# EFR32FG23A020F512GM40 register map
Vendor: Silicon Labs; Series: EFR32; File version: B
Registers are 32-bit, read-write, reset 0x0 unless marked. A register's access mark holds for its fields unless they carry their own. Offsets are from the block's base; [hi:lo] are bit positions.

## LFRCO_S — LFRCO_S Registers
Base 0x40024000
Same registers: LFRCO_NS 0x50024000
0x00 IPVERSION ro — Contains the LFRCO ip version.
  [31:0] IPVERSION — IP version ID
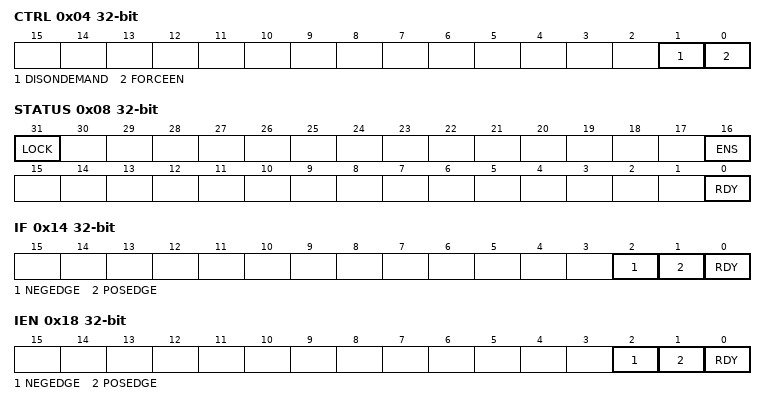
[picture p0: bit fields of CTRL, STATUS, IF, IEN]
0x04 CTRL — Control register
  [1] DISONDEMAND — Disable On-Demand
  [0] FORCEEN — Force Enable
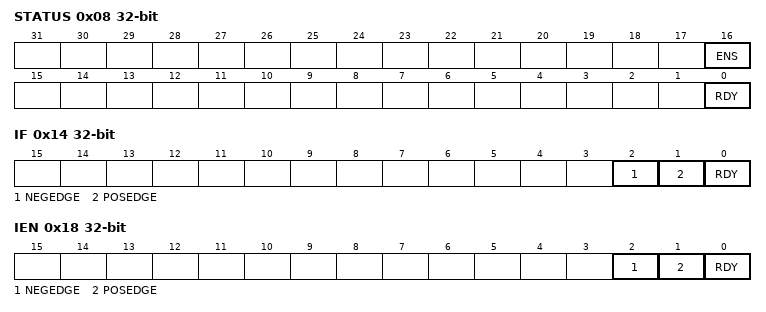
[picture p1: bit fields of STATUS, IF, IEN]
0x08 STATUS ro
  [31] LOCK — Lock Status
    0=UNLOCKED (Access to configuration registers not locked); 1=LOCKED (Access to configuration registers locked)
  [16] ENS — Enabled Status
  [0] RDY — Ready Status
0x0C CAL reset 0xA5 — Calibration register
  [7:0] FREQTRIM — Frequency Trim
0x14 IF — Interrupt flag register
  [2] NEGEDGE — Falling Edge Interrupt Flag
  [1] POSEDGE — Rising Edge Interrupt Flag
  [0] RDY — Ready Interrupt Flag
0x18 IEN — Interrupt enable register.
  [2] NEGEDGE — Falling Edge Interrupt Enable
  [1] POSEDGE — Rising Edge Interrupt Enable
  [0] RDY — Ready Interrupt Enable
0x1C SYNCBUSY ro — Synchronization busy register
  [0] CAL — CAL Busy
0x20 LOCK wo reset 0x2603 — Configuration lock register. Locks/unlocks access to cofiguration registers.
  [15:0] LOCKKEY
    0=LOCK (Lock Configuration Registers); 0x2603=UNLOCK (Unlock Configuaration Registers)

## ULFRCO_S — ULFRCO_S Registers
Base 0x40028000
Same registers: ULFRCO_NS 0x50028000
0x00 IPVERSION ro reset 0x1
  [31:0] IPVERSION — ULFRCO IP version
0x08 STATUS ro
  [16] ENS — Enable Status
  [0] RDY — Ready Status
0x14 IF
  [2] NEGEDGE — Negative Edge Interrupt Flag
  [1] POSEDGE — Positive Edge Interrupt Flag
  [0] RDY — Ready Interrupt Flag
0x18 IEN
  [2] NEGEDGE — Enable Negative Edge Interrupt
  [1] POSEDGE — Enable Positive Edge Interrupt
  [0] RDY — Enable Ready Interrupt

## MSC_S — MSC_S Registers
Base 0x40030000
Same registers: MSC_NS 0x50030000
0x00 IPVERSION ro reset 0x2
  [31:0] IPVERSION — IP Version ID
0x04 READCTRL reset 0x200000
  [21:20] MODE — Read Mode
    0=WS0 (Zero wait-states inserted in fetch or read transfers); 1=WS1 (One wait-state inserted for each fetch or read transfer. See Flash Wait-States table for details); 2=WS2 (Two wait-states inserted for eatch fetch or read transfer. See Flash Wait-States table for details); 3=WS3 (Three wait-states inserted for eatch fetch or read transfer. See Flash Wait-States table for details)
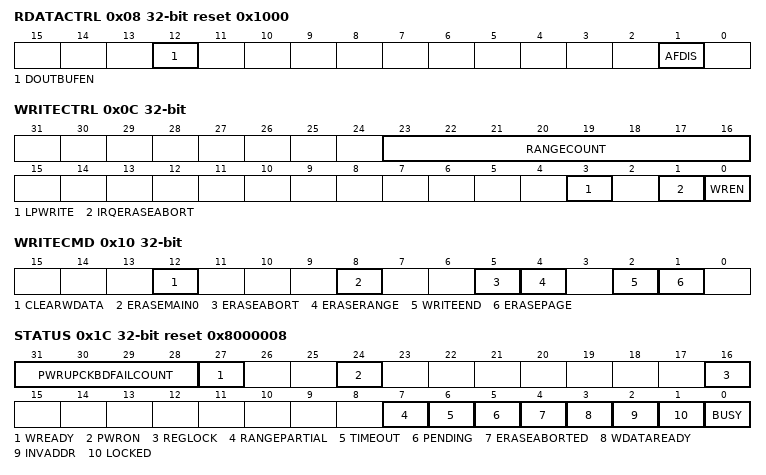
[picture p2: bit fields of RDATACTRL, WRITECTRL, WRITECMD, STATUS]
0x08 RDATACTRL reset 0x1000
  [12] DOUTBUFEN — Flash dout pipeline buffer enable
  [1] AFDIS — Automatic Invalidate Disable
0x0C WRITECTRL
  [23:16] RANGECOUNT — ErageRange Count
  [3] LPWRITE — Low-Power Erase
  [1] IRQERASEABORT — Abort Page Erase on Interrupt
  [0] WREN — Enable Write/Erase Controller
0x10 WRITECMD wo
  [12] CLEARWDATA — Clear WDATA state
  [8] ERASEMAIN0 — Mass erase region 0
  [5] ERASEABORT — Abort erase sequence
  [4] ERASERANGE — Erase range of pages
  [2] WRITEEND — End Write Mode
  [1] ERASEPAGE
0x14 ADDRB
  [31:0] ADDRB — Page Erase or Write Address Buffer
0x18 WDATA
  [31:0] DATAW — Write Data
0x1C STATUS ro reset 0x8000008
  [31:28] PWRUPCKBDFAILCOUNT — Flash power up checkerboard pattern chec
  [27] WREADY — Flash Write Ready
  [24] PWRON — Flash power on status
  [16] REGLOCK — Register Lock Status
    0=UNLOCKED; 1=LOCKED
  [7] RANGEPARTIAL — EraseRange with skipped locked pages
  [6] TIMEOUT — Write command timeout flag
  [5] PENDING — Write command is in queue
  [4] ERASEABORTED — The Current Flash Erase Operation Aborte
  [3] WDATAREADY — WDATA Write Ready
  [2] INVADDR — Invalid Write Address or Erase Page
  [1] LOCKED — Access Locked
  [0] BUSY — Erase/Write Busy
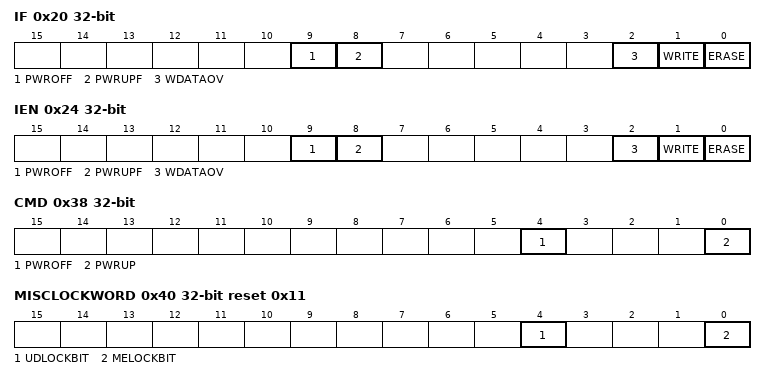
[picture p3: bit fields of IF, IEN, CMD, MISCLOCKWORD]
0x20 IF
  [9] PWROFF — Flash Power Off Sequence Complete Flag
  [8] PWRUPF — Flash Power Up Sequence Complete Flag
  [2] WDATAOV — Host write buffer overflow
  [1] WRITE — Host Write Done Interrupt Read Flag
  [0] ERASE — Host Erase Done Interrupt Read Flag
0x24 IEN
  [9] PWROFF — Flash Power Off Seq done irq enable
  [8] PWRUPF — Flash Power Up Seq done irq enable
  [2] WDATAOV — write data buffer overflow irq enable
  [1] WRITE — Write Done Interrupt enable
  [0] ERASE — Erase Done Interrupt enable
0x34 USERDATASIZE ro reset 0x4
  [5:0] USERDATASIZE
0x38 CMD wo
  [4] PWROFF — Flash power off/sleep command
  [0] PWRUP — Flash Power Up Command
0x3C LOCK wo
  [15:0] LOCKKEY — Configuration Lock
    0=LOCK; 0x1B71=UNLOCK
0x40 MISCLOCKWORD reset 0x11
  [4] UDLOCKBIT — User Data Lock
  [0] MELOCKBIT — Mass Erase Lock
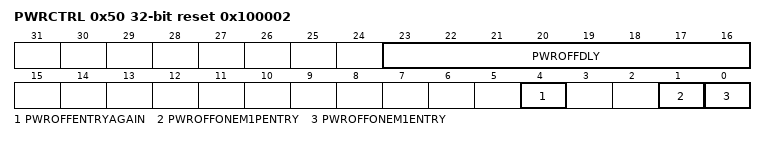
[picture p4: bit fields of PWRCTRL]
0x50 PWRCTRL reset 0x100002
  [23:16] PWROFFDLY — Power down delay
  [4] PWROFFENTRYAGAIN — POWER down flash again in EM1/EM1p
  [1] PWROFFONEM1PENTRY — Power down Flash macro when enter EM1P
  [0] PWROFFONEM1ENTRY — Power down Flash macro when enter EM1
0x120 PAGELOCK0
  [31:0] LOCKBIT — page lock bit
0x124 PAGELOCK1
  [31:0] LOCKBIT — page lock bit
